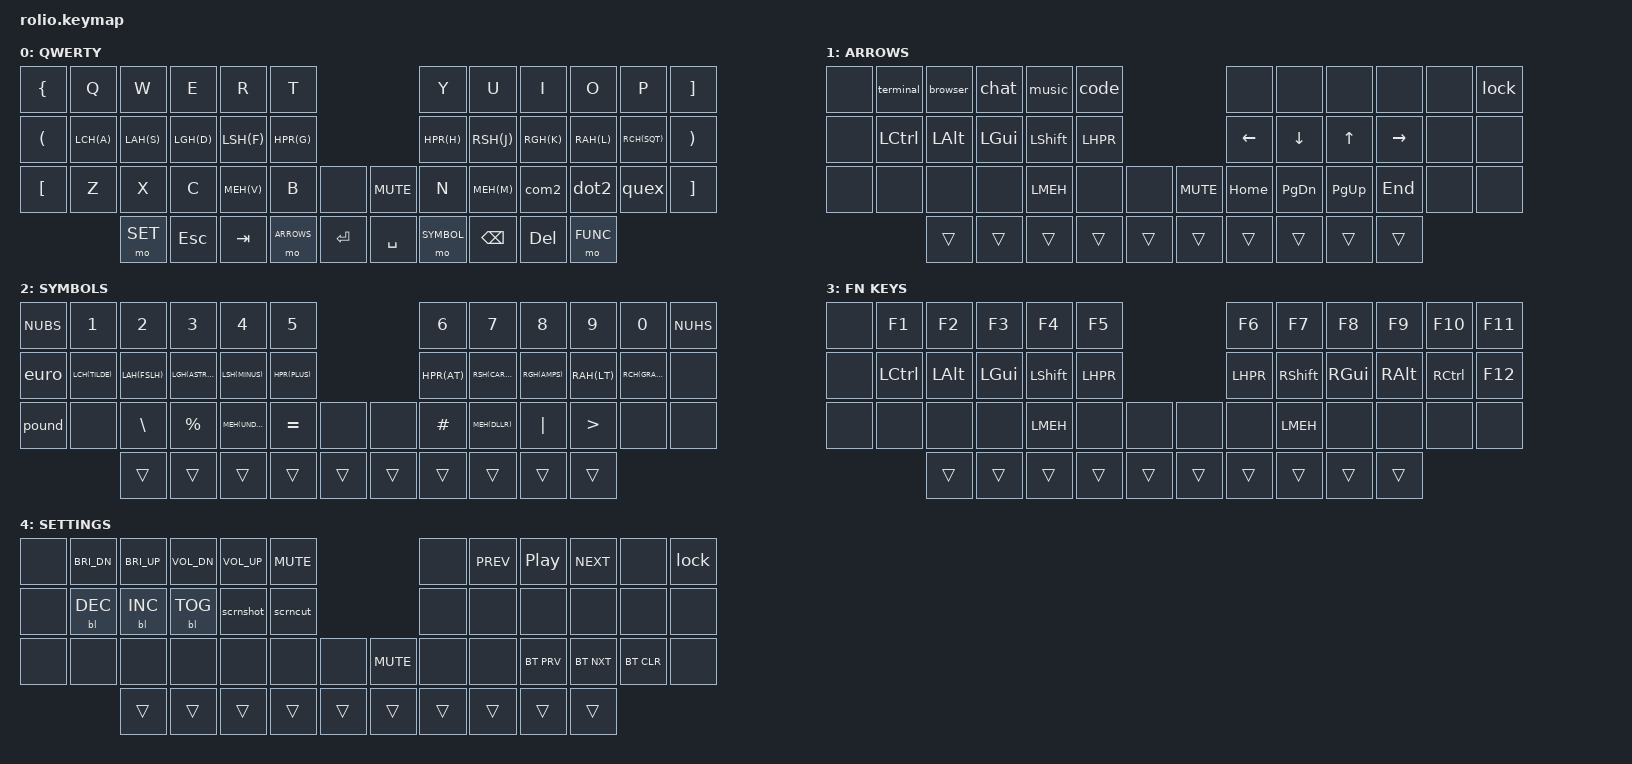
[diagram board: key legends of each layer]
/*
 * Copyright (c) 2023 The ZMK Contributors
 *
 * SPDX-License-Identifier: MIT
 */

#include <behaviors.dtsi>
#include <dt-bindings/zmk/keys.h>
#include <dt-bindings/zmk/bt.h>
#include <dt-bindings/zmk/outputs.h>
#include <dt-bindings/zmk/backlight.h>

#include "aliases.dtsi"
#include "behaviors.dtsi"
#include "macros.dtsi"

#define QWERTY 0
#define ARROWS 1
#define SYMBOL 2
#define FUNC  3
#define SET 4

/ {
    keymap {
        compatible = "zmk,keymap";

        qwerty {
            label = "QWERTY";
            bindings = <
            /*╭───────────┬───────────┬───────────┬───────────┬───────────┬───────────╮                           ╭───────────┬───────────┬───────────┬───────────┬───────────┬───────────╮*/
                &kp LBRC    &kp Q       &kp W       &kp E       &kp R       &kp T     /*                         */ &kp Y       &kp U       &kp I       &kp O       &kp P       &kp RBKT
            /*├───────────┼───────────┼───────────┼───────────┼───────────┼───────────┤                           ├───────────┼───────────┼───────────┼───────────┼───────────┼───────────┤*/
                &kp LPAR    LCH(A)      LAH(S)      LGH(D)      LSH(F)      HPR(G)    /*                         */ HPR(H)      RSH(J)      RGH(K)      RAH(L)      RCH(SQT)    &kp RPAR
            /*├───────────┼───────────┼───────────┼───────────┼───────────┼───────────┤───────────╮   ╭───────────├───────────┼───────────┼───────────┼───────────┼───────────┼───────────┤*/
                &kp LBKT    &kp Z       &kp X       &kp C       MEH(V)      &kp B       &none     /* */ &kp MUTE    &kp N       MEH(M)      &com2       &dot2       &quex       &kp RBKT
            /*╰───────────┴───────────┼───────────┼───────────┼───────────┼───────────┼───────────╮   ╭───────────┼───────────┼───────────┼───────────┼───────────┼───────────┴───────────╯*/
                                        &mo SET     &kp ESC     &kp TAB     &mo ARROWS  &kp RET   /* */ &kp SPACE   &mo SYMBOL  &kp BSPC    &kp DEL     &mo FUNC
            /*                        ╰───────────┴───────────┴───────────┴───────────┤           │   │           ├───────────┴───────────┴───────────┴───────────╯                        */
            /*                                                                        ╰───────────╯   ╰───────────╯                                                                        */
            >;

            sensor-bindings = <&inc_dec_kp BRI_UP BRI_DN &inc_dec_kp VOL_UP VOL_DN>;
        };

        arrows {
            label = "ARROWS";
            bindings = <
            /*╭───────────┬───────────┬───────────┬───────────┬───────────┬───────────╮                           ╭───────────┬───────────┬───────────┬───────────┬───────────┬───────────╮*/
                &none       &terminal   &browser    &chat       &music      &code     /*                         */ &none       &none       &none       &none       &none       &lock
            /*├───────────┼───────────┼───────────┼───────────┼───────────┼───────────┤                           ├───────────┼───────────┼───────────┼───────────┼───────────┼───────────┤*/
                &none       &kp LCTRL   &kp LALT    &kp LGUI    &kp LSHIFT  &kp LHPR  /*                         */ &kp LEFT    &kp DOWN    &kp UP      &kp RIGHT   &none       &none 
            /*├───────────┼───────────┼───────────┼───────────┼───────────┼───────────┤───────────╮   ╭───────────├───────────┼───────────┼───────────┼───────────┼───────────┼───────────┤*/
                &none       &none       &none       &none       &kp LMEH    &none       &none     /* */ &kp MUTE    &kp HOME    &kp PG_DN   &kp PG_UP   &kp END     &none       &none 
            /*╰───────────┴───────────┼───────────┼───────────┼───────────┼───────────┼───────────╮   ╭───────────┼───────────┼───────────┼───────────┼───────────┼───────────┴───────────╯*/
                                        &trans      &trans      &trans      &trans      &trans    /* */ &trans      &trans      &trans      &trans      &trans
            /*                        ╰───────────┴───────────┴───────────┴───────────┤           │   │           ├───────────┴───────────┴───────────┴───────────╯                        */
            /*                                                                        ╰───────────╯   ╰───────────╯                                                                        */
            >;

            sensor-bindings = <&inc_dec_kp BRI_UP BRI_DN &inc_dec_kp VOL_UP VOL_DN>;
        };

        symbols {
            label = "SYMBOLS";
            bindings = <  
            /*╭───────────┬───────────┬───────────┬───────────┬───────────┬───────────╮                           ╭───────────┬───────────┬───────────┬───────────┬───────────┬───────────╮*/
                &kp NUBS    &kp N1      &kp N2      &kp N3      &kp N4      &kp N5    /*                         */ &kp N6      &kp N7      &kp N8      &kp N9      &kp N0      &kp NUHS
            /*├───────────┼───────────┼───────────┼───────────┼───────────┼───────────┤                           ├───────────┼───────────┼───────────┼───────────┼───────────┼───────────┤*/
                &euro       LCH(TILDE)  LAH(FSLH)   LGH(ASTRK)  LSH(MINUS)  HPR(PLUS) /*                         */ HPR(AT)     RSH(CARET)  RGH(AMPS)   RAH(LT)     RCH(GRAVE)  &none 
            /*├───────────┼───────────┼───────────┼───────────┼───────────┼───────────┤───────────╮   ╭───────────├───────────┼───────────┼───────────┼───────────┼───────────┼───────────┤*/
                &pound      &none       &kp BSLH    &kp PRCNT   MEH(UNDER)  &kp EQUAL   &none     /* */ &none       &kp HASH    MEH(DLLR)   &kp PIPE    &kp GT      &none       &none 
            /*╰───────────┴───────────┼───────────┼───────────┼───────────┼───────────┼───────────╮   ╭───────────┼───────────┼───────────┼───────────┼───────────┼───────────┴───────────╯*/
                                        &trans      &trans      &trans      &trans      &trans    /* */ &trans      &trans      &trans      &trans      &trans
            /*                        ╰───────────┴───────────┴───────────┴───────────┤           │   │           ├───────────┴───────────┴───────────┴───────────╯                        */
            /*                                                                        ╰───────────╯   ╰───────────╯                                                                        */
            >;

            sensor-bindings = <&inc_dec_kp BRI_UP BRI_DN &inc_dec_kp VOL_UP VOL_DN>;
        };

        function {
            label = "FN KEYS";
            bindings = <
            /*╭───────────┬───────────┬───────────┬───────────┬───────────┬───────────╮                           ╭───────────┬───────────┬───────────┬───────────┬───────────┬───────────╮*/
                &none       &kp F1      &kp F2      &kp F3      &kp F4      &kp F5    /*                         */ &kp F6      &kp F7      &kp F8      &kp F9      &kp F10     &kp F11
            /*├───────────┼───────────┼───────────┼───────────┼───────────┼───────────┤                           ├───────────┼───────────┼───────────┼───────────┼───────────┼───────────┤*/
                &none       &kp LCTRL   &kp LALT    &kp LGUI    &kp LSHIFT  &kp LHPR  /*                         */ &kp LHPR    &kp RSHIFT  &kp RGUI    &kp RALT    &kp RCTRL   &kp F12
            /*├───────────┼───────────┼───────────┼───────────┼───────────┼───────────┤───────────╮   ╭───────────├───────────┼───────────┼───────────┼───────────┼───────────┼───────────┤*/
                &none       &none       &none       &none       &kp LMEH    &none       &none     /* */ &none       &none       &kp LMEH    &none       &none       &none       &none
            /*╰───────────┴───────────┼───────────┼───────────┼───────────┼───────────┼───────────╮   ╭───────────┼───────────┼───────────┼───────────┼───────────┼───────────┴───────────╯*/
                                        &trans      &trans      &trans      &trans      &trans    /* */ &trans      &trans      &trans      &trans      &trans
            /*                        ╰───────────┴───────────┴───────────┴───────────┤           │   │           ├───────────┴───────────┴───────────┴───────────╯                        */
            /*                                                                        ╰───────────╯   ╰───────────╯                                                                        */
            >;

            sensor-bindings = <&inc_dec_kp BRI_UP BRI_DN &inc_dec_kp VOL_UP VOL_DN>;
        };

        settings {
            label = "SETTINGS";
            bindings = <
            /*╭───────────┬───────────┬───────────┬───────────┬───────────┬───────────╮                           ╭───────────┬───────────┬───────────┬───────────┬───────────┬───────────╮*/
                &none       &kp BRI_DN  &kp BRI_UP  &kp VOL_DN  &kp VOL_UP  &kp MUTE  /*                         */ &none       &kp C_PREV  &kp C_PP    &kp C_NEXT  &none       &lock
            /*├───────────┼───────────┼───────────┼───────────┼───────────┼───────────┤                           ├───────────┼───────────┼───────────┼───────────┼───────────┼───────────┤*/
                &none       &bl BL_DEC  &bl BL_INC  &bl BL_TOG  &scrnshot   &scrncut  /*                         */ &none       &none       &none       &none       &none       &none 
            /*├───────────┼───────────┼───────────┼───────────┼───────────┼───────────┤───────────╮   ╭───────────├───────────┼───────────┼───────────┼───────────┼───────────┼───────────┤*/
                &none       &none       &none       &none       &none       &none       &none     /* */ &kp MUTE    &none       &none       &bt BT_PRV  &bt BT_NXT  &bt BT_CLR  &none 
            /*╰───────────┴───────────┼───────────┼───────────┼───────────┼───────────┼───────────╮   ╭───────────┼───────────┼───────────┼───────────┼───────────┼───────────┴───────────╯*/
                                        &trans      &trans      &trans      &trans      &trans    /* */ &trans      &trans      &trans      &trans      &trans
            /*                        ╰───────────┴───────────┴───────────┴───────────┤           │   │           ├───────────┴───────────┴───────────┴───────────╯                        */
            /*                                                                        ╰───────────╯   ╰───────────╯                                                                        */
            >;

            sensor-bindings = <&inc_dec_kp BRI_UP BRI_DN &inc_dec_kp VOL_UP VOL_DN>;
        };
    };
};
